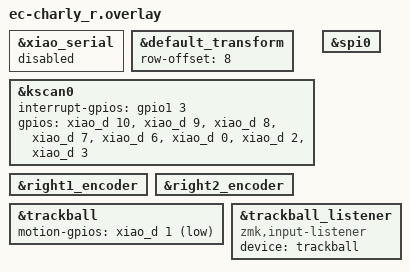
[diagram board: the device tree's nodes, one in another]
#include "ec-charly.dtsi"
#include <input/processors.dtsi>
#include <dt-bindings/zmk/input_transform.h>

&xiao_serial { status = "disabled"; };

&default_transform {
    row-offset = <8>;
};

&kscan0 {
    interrupt-gpios = <&gpio1 3 (GPIO_ACTIVE_HIGH | GPIO_PULL_DOWN)>;
    gpios = 
        <&xiao_d 10 GPIO_ACTIVE_HIGH>,
        <&xiao_d 9 GPIO_ACTIVE_HIGH>,
        <&xiao_d 8 GPIO_ACTIVE_HIGH>,
        <&xiao_d 7 GPIO_ACTIVE_HIGH>,
        <&xiao_d 6 GPIO_ACTIVE_HIGH>,
        <&xiao_d 0 GPIO_ACTIVE_HIGH>,
        <&xiao_d 2 GPIO_ACTIVE_HIGH>,
        <&xiao_d 3 GPIO_ACTIVE_HIGH>;
};

&right1_encoder { status = "okay"; };
&right2_encoder { status = "okay"; };

&spi0 {
    status = "okay";
};

&trackball {
    status = "okay";
    /* 右側だけで D1 (P0.03) ピンを割り当てる */
    motion-gpios = <&xiao_d 1 (GPIO_ACTIVE_LOW | GPIO_PULL_UP)>;
};

&trackball_listener {
    status = "okay";
    compatible = "zmk,input-listener";
    device = <&trackball>;
};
